# STM32F37x register map
File version: 1.1
Registers are 32-bit, read-write, reset 0x0 unless marked. A register's access mark holds for its fields unless they carry their own. Offsets are from the block's base; [hi:lo] are bit positions; {n}, {i} and the like mark numbered series.

## SYSCFG — System configuration controller
Base 0x40010000
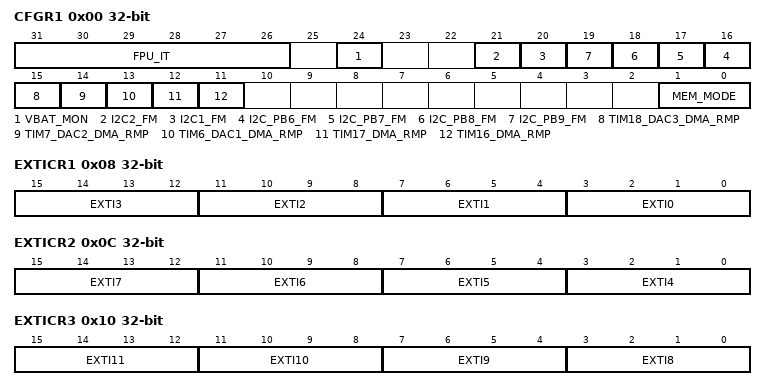
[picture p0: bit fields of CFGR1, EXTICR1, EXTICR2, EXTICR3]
0x00 CFGR1 — configuration register 1
  [31:26] FPU_IT — Interrupt enable bits from FPU
  [24] VBAT_MON — VBAT monitoring enable
  [21] I2C2_FM — I2C2 Fast Mode Plus
  [20] I2C1_FM — I2C1 Fast Mode Plus
  [n+10] I2C_PB{n}_FM (n=6..9) — Fast Mode Plus (FM+) driving capability activation bits.
  [15] TIM18_DAC3_DMA_RMP — TIM18 and DAC3 DMA request remapping bit
  [14] TIM7_DAC2_DMA_RMP — TIM7 and DAC2 DMA request remapping bit
  [13] TIM6_DAC1_DMA_RMP — TIM6 and DAC1 DMA request remapping bit
  [12] TIM17_DMA_RMP — TIM17 DMA request remapping bit
  [11] TIM16_DMA_RMP — TIM16 DMA request remapping bit
  [1:0] MEM_MODE — Memory mapping selection bits
0x08 EXTICR1 — external interrupt configuration register 1
  [4n+3:4n] EXTI{n} (n=0..3) — EXTI {n} configuration bits
0x0C EXTICR2 — external interrupt configuration register 2
  [4n-13:4n-16] EXTI{n} (n=4..7) — EXTI {n} configuration bits
0x10 EXTICR3 — external interrupt configuration register 3
  [4n-29:4n-32] EXTI{n} (n=8..11) — EXTI {n} configuration bits
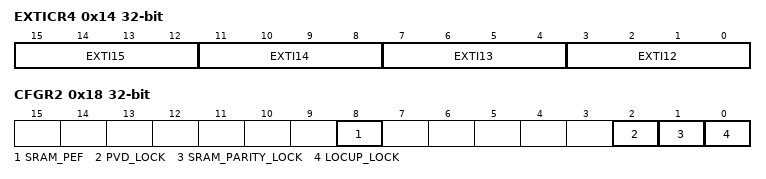
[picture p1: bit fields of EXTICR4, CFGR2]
0x14 EXTICR4 — external interrupt configuration register 4
  [4n-45:4n-48] EXTI{n} (n=12..15) — EXTI {n} configuration bits
0x18 CFGR2 — configuration register 2
  [8] SRAM_PEF — SRAM parity flag
  [2] PVD_LOCK — PVD lock enable bit
  [1] SRAM_PARITY_LOCK — SRAM parity lock bit
  [0] LOCUP_LOCK — Cortex-M4 LOCKUP bit enable bit

## COMP — Comparator
Base 0x40007C00
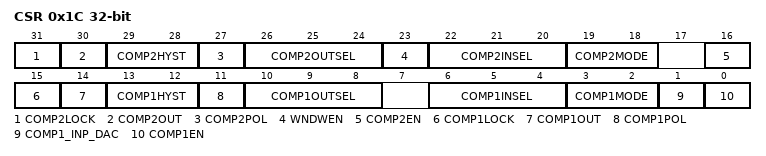
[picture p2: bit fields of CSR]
0x1C CSR access per field — control and status register
  [31] COMP2LOCK rw — Comparator 2 lock
  [30] COMP2OUT ro — Comparator 2 output
  [29:28] COMP2HYST rw — Comparator 2 hysteresis
  [27] COMP2POL rw — Comparator 2 output polarity
  [26:24] COMP2OUTSEL rw — Comparator 2 output selection
  [23] WNDWEN rw — Window mode enable
  [22:20] COMP2INSEL rw — Comparator 2 inverting input selection
  [19:18] COMP2MODE rw — Comparator 2 mode
  [16] COMP2EN rw — Comparator 2 enable
  [15] COMP1LOCK rw — Comparator 1 lock
  [14] COMP1OUT ro — Comparator 1 output
  [13:12] COMP1HYST rw — Comparator 1 hysteresis
  [11] COMP1POL rw — Comparator 1 output polarity
  [10:8] COMP1OUTSEL rw — Comparator 1 output selection
  [6:4] COMP1INSEL rw — Comparator 1 inverting input selection
  [3:2] COMP1MODE rw — Comparator 1 mode
  [1] COMP1_INP_DAC rw
  [0] COMP1EN rw — Comparator 1 enable

## CEC — HDMI-CEC controller
Base 0x40007800
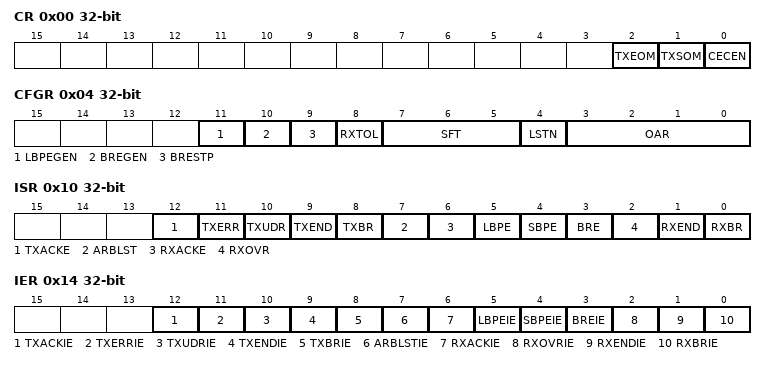
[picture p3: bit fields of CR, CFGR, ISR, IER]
0x00 CR — control register
  [2] TXEOM — Tx End Of Message
  [1] TXSOM — Tx start of message
  [0] CECEN — CEC Enable
0x04 CFGR — configuration register
  [11] LBPEGEN — Generate Error-Bit on Long Bit Period Error
  [10] BREGEN — Generate error-bit on bit rising error
  [9] BRESTP — Rx-stop on bit rising error
  [8] RXTOL — Rx-Tolerance
  [7:5] SFT — Signal Free Time
  [4] LSTN — Listen mode
  [3:0] OAR — Own Address
0x08 TXDR wo — Tx data register
  [7:0] TXD — Tx Data register
0x0C RXDR ro — Rx Data Register
  [7:0] RXDR — CEC Rx Data Register
0x10 ISR — Interrupt and Status Register
  [12] TXACKE — Tx-Missing acknowledge error
  [11] TXERR — Tx-Error
  [10] TXUDR — Tx-Buffer Underrun
  [9] TXEND — End of Transmission
  [8] TXBR — Tx-Byte Request
  [7] ARBLST — Arbitration Lost
  [6] RXACKE — Rx-Missing Acknowledge
  [5] LBPE — Rx-Long Bit Period Error
  [4] SBPE — Rx-Short Bit period error
  [3] BRE — Rx-Bit rising error
  [2] RXOVR — Rx-Overrun
  [1] RXEND — End Of Reception
  [0] RXBR — Rx-Byte Received
0x14 IER — interrupt enable register
  [12] TXACKIE — Tx-Missing Acknowledge Error Interrupt Enable
  [11] TXERRIE — Tx-Error Interrupt Enable
  [10] TXUDRIE — Tx-Underrun interrupt enable
  [9] TXENDIE — Tx-End of message interrupt enable
  [8] TXBRIE — Tx-Byte Request Interrupt Enable
  [7] ARBLSTIE — Arbitration Lost Interrupt Enable
  [6] RXACKIE — Rx-Missing Acknowledge Error Interrupt Enable
  [5] LBPEIE — Long Bit Period Error Interrupt Enable
  [4] SBPEIE — Short Bit Period Error Interrupt Enable
  [3] BREIE — Bit Rising Error Interrupt Enable
  [2] RXOVRIE — Rx-Buffer Overrun Interrupt Enable
  [1] RXENDIE — End Of Reception Interrupt Enable
  [0] RXBRIE — Rx-Byte Received Interrupt Enable
